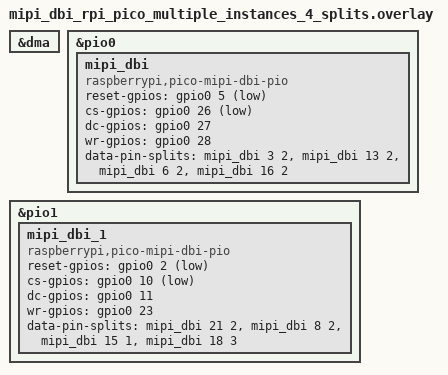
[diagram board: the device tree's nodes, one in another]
/*
 * Copyright 2025 Christoph Schnetzler
 *
 * SPDX-License-Identifier: Apache-2.0
 */

&dma {
	status = "okay";
};

&pio0 {
	status = "okay";

	mipi_dbi: mipi_dbi {
		status = "okay";
		compatible = "raspberrypi,pico-mipi-dbi-pio";
		reset-gpios = <&gpio0 5 GPIO_ACTIVE_LOW>;
		cs-gpios = <&gpio0 26 GPIO_ACTIVE_LOW>;
		dc-gpios = <&gpio0 27 GPIO_ACTIVE_HIGH>;
		wr-gpios = <&gpio0 28 GPIO_ACTIVE_HIGH>;
		data-pin-splits = <&mipi_dbi 3 2>,
				  <&mipi_dbi 13 2>,
				  <&mipi_dbi 6 2>,
				  <&mipi_dbi 16 2>;
		#address-cells = <1>;
		#size-cells = <0>;
		#data-pin-split-cells = <2>;
	};
};

&pio1 {
	status = "okay";

	mipi_dbi_1: mipi_dbi_1 {
		status = "okay";
		compatible = "raspberrypi,pico-mipi-dbi-pio";
		reset-gpios = <&gpio0 2 GPIO_ACTIVE_LOW>;
		cs-gpios = <&gpio0 10 GPIO_ACTIVE_LOW>;
		dc-gpios = <&gpio0 11 GPIO_ACTIVE_HIGH>;
		wr-gpios = <&gpio0 23 GPIO_ACTIVE_HIGH>;
		data-pin-splits = <&mipi_dbi 21 2>,
				  <&mipi_dbi 8 2>,
				  <&mipi_dbi 15 1>,
				  <&mipi_dbi 18 3>;
		#address-cells = <1>;
		#size-cells = <0>;
		#data-pin-split-cells = <2>;
	};
};
